# RA register map
Vendor: Renesas; Series: All Chips; File version: x.xx
Registers are 32-bit, read-write, reset 0x0 unless marked. A register's access mark holds for its fields unless they carry their own. Offsets are from the block's base; [hi:lo] are bit positions; 'fields as' and 'values as' point back to an identical list.

## R_TSN — Temperature Sensor
Base 0x407EC000
0x228 TSCDRL 8-bit ro reset not defined — Temperature Sensor Calibration Data Register L
  [7:0] TSCDRL — The calibration data stores the lower 8 bits of the convertedvalue.
0x229 TSCDRH 8-bit ro reset not defined — Temperature Sensor Calibration Data Register H
  [7:0] TSCDRH — The calibration data stores the higher 8 bits of the convertedvalue.

## R_TSN_CAL — Temperature Sensor
Base 0x407FB17C
0x00 TSCDR ro reset not defined — Temperature Sensor 32 bit Calibration Data Register
  [31:0] TSCDR — The 32 bit TSCDR register stores temperature sensor calibration converted value.

## R_TSN_CTRL — Temperature Sensor
Base 0x4005D000
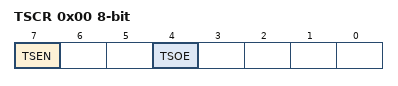
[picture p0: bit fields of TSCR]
0x00 TSCR 8-bit — Temperature Sensor Control Register
  [7] TSEN — Temperature Sensor Output Enable
    0=Stops the temperature sensor; 1=Starts the temperature sensor
  [4] TSOE — Temperature Sensor Enable
    0=Disables output from the temperature sensor to the 12-bit A/D converter; 1=Enables output from the temperature sensor to the 12-bit A/D converter

## R_WDT — Watchdog Timer
Base 0x40044200
0x00 WDTRR 8-bit reset 0xFF — WDT Refresh Register
  [7:0] WDTRR — WDTRR is an 8-bit register that refreshes the down-counter of the WDT.
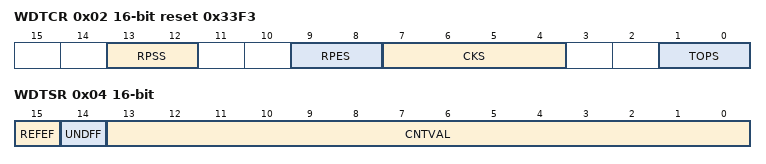
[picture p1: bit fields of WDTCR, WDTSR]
0x02 WDTCR 16-bit reset 0x33F3 — WDT Control Register
  [13:12] RPSS — Window Start Position Selection
    0=25%; 1=50%; 2=75%; 3=100% (window start position is not specified)
  [9:8] RPES — Window End Position Selection
    0=75%; 1=50%; 2=25%; 3=0% (window end position is not specified)
  [7:4] CKS — Clock Division Ratio Selection
    1=PCLK/4; 4=PCLK/64; 15=PCLK/128; 6=PCLK/512; 7=PCLK/2048; 8=PCLK/8192; other=others (setting prohibited)
  [1:0] TOPS — Timeout Period Selection
    0=1,024 cycles (03FFh); 1=4,096 cycles (0FFFh); 2=8,192 cycles (1FFFh); 3=16,384 cycles (3FFFh)
0x04 WDTSR 16-bit — WDT Status Register
  [15] REFEF write-0-clears read-modifies — Refresh Error Flag
    0=No refresh error occurred; 1=Refresh error occurred
  [14] UNDFF write-0-clears read-modifies — Underflow Flag
    0=No underflow occurred; 1=Underflow occurred
  [13:0] CNTVAL ro — Down-Counter Value
0x06 WDTRCR 8-bit reset 0x80 — WDT Reset Control Register
  [7] RSTIRQS — Reset Interrupt Request Selection
    0=Non-maskable interrupt request or interrupt request output is enabled; 1=Reset output is enabled
0x08 WDTCSTPR 8-bit reset 0x80 — WDT Count Stop Control Register
  [7] SLCSTP — Sleep-Mode Count Stop Control
    0=Count stop is disabled; 1=Count is stopped at a transition to sleep mode

## R_TZF — TrustZone Filter
Base 0x40000E00
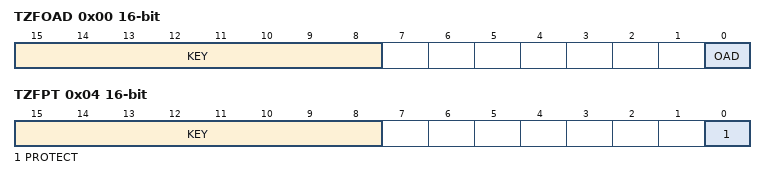
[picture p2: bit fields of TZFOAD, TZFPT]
0x00 TZFOAD 16-bit — TrustZone Filter Operation After Detection Register
  [15:8] KEY wo — KeyCode
  [0] OAD — Operation after detection
    0=Reset; 1=Non-maskable interrupt
0x04 TZFPT 16-bit — TrustZone Filter Protect Register
  [15:8] KEY wo — KeyCode
  [0] PROTECT — Protection of register
    0=All Bus TrustZone Filter register writing is protected. Read is possible.; 1=All Bus TrustZone Filter register writing is possible
0x180 TZFSAR reset 0xFFFFFFFF — TrustZone Filter Security Attribution Register
  [0] TZFSA0 — Security attributes of registers for TrustZone Filter
    0=Secure; 1=Non-secure

## R_CACHE
Base 0x40007000
0x00 CCACTL — C-Cache Control Register
  [0] ENC — C-Cache Enable
    0=Disable C-cache; 1=Enable C-cache
0x04 CCAFCT — C-Cache Flush Control Register
  [0] FC — C-Cache Flush
    0=No action; 1=C-cache line flush (all lines invalidated)
0x08 CCALCF reset 0x101 — C-Cache Line Configuration Register
  [1:0] CC — C-Cache Line Size
    0=Prohibited; 1=Cache line size 32 bytes; 2=Cache line size 64 bytes; 3=Prohibited
0x40 SCACTL — S-Cache Control Register
  [0] ENS — S-Cache Enable
    0=Disable S-cache; 1=Enable S-cache
0x44 SCAFCT — S-Cache Flush Control Register
  [0] FS — S-Cache Flush
    0=No action; 1=S-cache line flush (all lines invalidated)
0x48 SCALCF reset 0x101 — S-Cache Line Configuration Register
  [1:0] CS — S-Cache Line Size
    values as CCALCF.CC
0x200 CAPOAD — Cache Parity Error Operation After Detection Register
  [0] OAD — Operation after Detection
    0=Non-maskable interrupt; 1=Reset
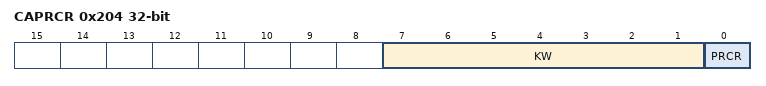
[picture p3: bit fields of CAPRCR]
0x204 CAPRCR — Cache Protection Register
  [7:1] KW — Write key code
  [0] PRCR — Register Write Control
    0=Disable writes to protected registers; 1=Enable writes to protected registers
